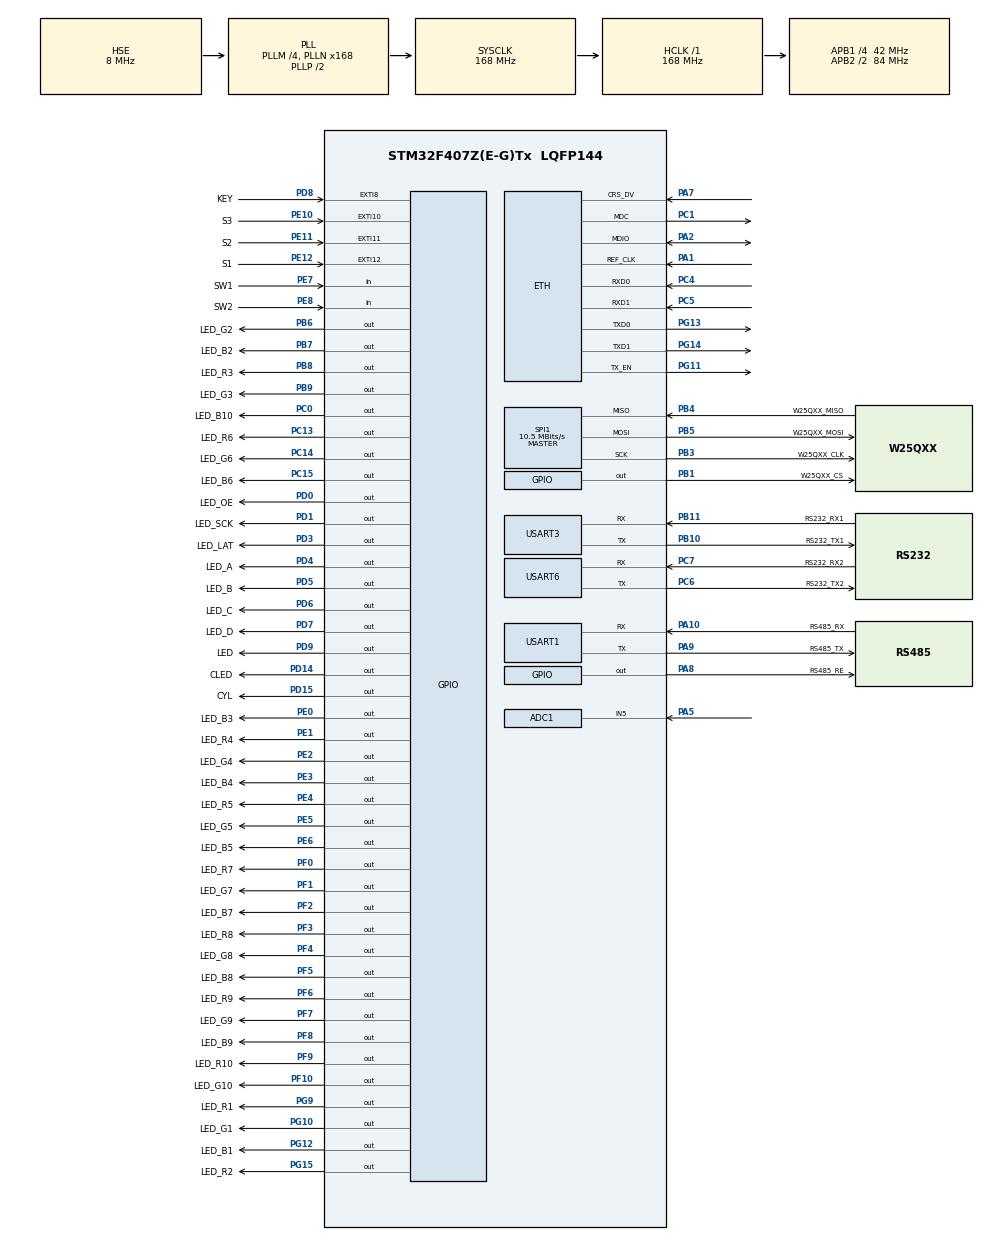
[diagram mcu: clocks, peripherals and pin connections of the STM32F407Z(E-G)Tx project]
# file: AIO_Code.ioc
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ADC1.Channel-0\#ChannelRegularConversion=ADC_CHANNEL_5
ADC1.NbrOfConversionFlag=1
ADC1.Rank-0\#ChannelRegularConversion=1
ADC1.SamplingTime-0\#ChannelRegularConversion=ADC_SAMPLETIME_3CYCLES
ADC1.master=1
Dma.Request0=USART1_RX
Dma.Request1=USART1_TX
Dma.Request2=USART3_RX
Dma.Request3=USART3_TX
Dma.Request4=USART6_RX
Dma.Request5=USART6_TX
Dma.Request6=SPI1_RX
Dma.Request7=SPI1_TX
Dma.SPI1_RX.6.Direction=DMA_PERIPH_TO_MEMORY
Dma.SPI1_RX.6.FIFOMode=DMA_FIFOMODE_DISABLE
Dma.SPI1_RX.6.Instance=DMA2_Stream0
Dma.SPI1_RX.6.MemDataAlignment=DMA_MDATAALIGN_BYTE
Dma.SPI1_RX.6.MemInc=DMA_MINC_ENABLE
Dma.SPI1_RX.6.Mode=DMA_NORMAL
Dma.SPI1_RX.6.PeriphDataAlignment=DMA_PDATAALIGN_BYTE
Dma.SPI1_RX.6.PeriphInc=DMA_PINC_DISABLE
Dma.SPI1_RX.6.Priority=DMA_PRIORITY_LOW
Dma.SPI1_TX.7.Direction=DMA_MEMORY_TO_PERIPH
Dma.SPI1_TX.7.FIFOMode=DMA_FIFOMODE_DISABLE
Dma.SPI1_TX.7.Instance=DMA2_Stream3
Dma.SPI1_TX.7.MemDataAlignment=DMA_MDATAALIGN_BYTE
Dma.SPI1_TX.7.MemInc=DMA_MINC_ENABLE
Dma.SPI1_TX.7.Mode=DMA_NORMAL
Dma.SPI1_TX.7.PeriphDataAlignment=DMA_PDATAALIGN_BYTE
Dma.SPI1_TX.7.PeriphInc=DMA_PINC_DISABLE
Dma.SPI1_TX.7.Priority=DMA_PRIORITY_LOW
Dma.USART1_RX.0.Direction=DMA_PERIPH_TO_MEMORY
Dma.USART1_RX.0.FIFOMode=DMA_FIFOMODE_DISABLE
Dma.USART1_RX.0.Instance=DMA2_Stream5
Dma.USART1_RX.0.MemDataAlignment=DMA_MDATAALIGN_BYTE
Dma.USART1_RX.0.MemInc=DMA_MINC_ENABLE
Dma.USART1_RX.0.Mode=DMA_NORMAL
Dma.USART1_RX.0.PeriphDataAlignment=DMA_PDATAALIGN_BYTE
Dma.USART1_RX.0.PeriphInc=DMA_PINC_DISABLE
Dma.USART1_RX.0.Priority=DMA_PRIORITY_LOW
Dma.USART1_TX.1.Direction=DMA_MEMORY_TO_PERIPH
Dma.USART1_TX.1.FIFOMode=DMA_FIFOMODE_DISABLE
Dma.USART1_TX.1.Instance=DMA2_Stream7
Dma.USART1_TX.1.MemDataAlignment=DMA_MDATAALIGN_BYTE
Dma.USART1_TX.1.MemInc=DMA_MINC_ENABLE
Dma.USART1_TX.1.Mode=DMA_NORMAL
Dma.USART1_TX.1.PeriphDataAlignment=DMA_PDATAALIGN_BYTE
Dma.USART1_TX.1.PeriphInc=DMA_PINC_DISABLE
Dma.USART1_TX.1.Priority=DMA_PRIORITY_LOW
Dma.USART3_RX.2.Direction=DMA_PERIPH_TO_MEMORY
Dma.USART3_RX.2.FIFOMode=DMA_FIFOMODE_DISABLE
Dma.USART3_RX.2.Instance=DMA1_Stream1
Dma.USART3_RX.2.MemDataAlignment=DMA_MDATAALIGN_BYTE
Dma.USART3_RX.2.MemInc=DMA_MINC_ENABLE
Dma.USART3_RX.2.Mode=DMA_NORMAL
Dma.USART3_RX.2.PeriphDataAlignment=DMA_PDATAALIGN_BYTE
Dma.USART3_RX.2.PeriphInc=DMA_PINC_DISABLE
Dma.USART3_RX.2.Priority=DMA_PRIORITY_LOW
Dma.USART3_TX.3.Direction=DMA_MEMORY_TO_PERIPH
Dma.USART3_TX.3.FIFOMode=DMA_FIFOMODE_DISABLE
Dma.USART3_TX.3.Instance=DMA1_Stream3
Dma.USART3_TX.3.MemDataAlignment=DMA_MDATAALIGN_BYTE
Dma.USART3_TX.3.MemInc=DMA_MINC_ENABLE
Dma.USART3_TX.3.Mode=DMA_NORMAL
Dma.USART3_TX.3.PeriphDataAlignment=DMA_PDATAALIGN_BYTE
Dma.USART3_TX.3.PeriphInc=DMA_PINC_DISABLE
Dma.USART3_TX.3.Priority=DMA_PRIORITY_LOW
Dma.USART6_RX.4.Direction=DMA_PERIPH_TO_MEMORY
Dma.USART6_RX.4.FIFOMode=DMA_FIFOMODE_DISABLE
Dma.USART6_RX.4.Instance=DMA2_Stream1
Dma.USART6_RX.4.MemDataAlignment=DMA_MDATAALIGN_BYTE
Dma.USART6_RX.4.MemInc=DMA_MINC_ENABLE
Dma.USART6_RX.4.Mode=DMA_NORMAL
Dma.USART6_RX.4.PeriphDataAlignment=DMA_PDATAALIGN_BYTE
Dma.USART6_RX.4.PeriphInc=DMA_PINC_DISABLE
Dma.USART6_RX.4.Priority=DMA_PRIORITY_LOW
Dma.USART6_TX.5.Direction=DMA_MEMORY_TO_PERIPH
Dma.USART6_TX.5.FIFOMode=DMA_FIFOMODE_DISABLE
Dma.USART6_TX.5.Instance=DMA2_Stream6
Dma.USART6_TX.5.MemDataAlignment=DMA_MDATAALIGN_BYTE
Dma.USART6_TX.5.MemInc=DMA_MINC_ENABLE
Dma.USART6_TX.5.Mode=DMA_NORMAL
Dma.USART6_TX.5.PeriphDataAlignment=DMA_PDATAALIGN_BYTE
Dma.USART6_TX.5.PeriphInc=DMA_PINC_DISABLE
Dma.USART6_TX.5.Priority=DMA_PRIORITY_LOW
ETH.MediaInterface=HAL_ETH_RMII_MODE
FREERTOS.Tasks01=defaultTask,24,256,StartDefaultTask,Default,NULL,Dynamic,NULL,NULL
FREERTOS.configTOTAL_HEAP_SIZE=32768
IWDG.Prescaler=IWDG_PRESCALER_64
IWDG.Reload=2499
LWIP.BSP.number=1
LWIP.GATEWAY_ADDRESS=192.168.001.001
LWIP.IP_ADDRESS=192.168.001.100
LWIP.LWIP_DHCP=0
LWIP.LWIP_STATS=0
LWIP.MEMP_NUM_TCP_PCB=8
LWIP.MEMP_NUM_UDP_PCB=10
LWIP.MEM_SIZE=20*1024
LWIP.NETMASK_ADDRESS=255.255.255.000
LWIP.Version=v2.1.2_Cube
LWIP0.BSP.STBoard=false
LWIP0.BSP.api=BSP_COMPONENT_DRIVER
LWIP0.BSP.component=DP83848
LWIP0.BSP.instance=DP83848
LWIP0.BSP.name=Driver_PHY
LWIP0.BSP.semaphore=S_DP83848
LWIP0.BSP.solution=DP83848
Mcu.Family=STM32F4
Mcu.Name=STM32F407Z(E-G)Tx
Mcu.Package=LQFP144
NVIC.DMA1_Stream1_IRQn=true\:8\:0\:true\:false\:true\:true\:false\:true\:true
NVIC.DMA1_Stream3_IRQn=true\:8\:0\:true\:false\:true\:true\:false\:true\:true
NVIC.DMA2_Stream0_IRQn=true\:5\:0\:false\:false\:true\:true\:false\:true\:true
NVIC.DMA2_Stream1_IRQn=true\:8\:0\:true\:false\:true\:true\:false\:true\:true
NVIC.DMA2_Stream3_IRQn=true\:5\:0\:false\:false\:true\:true\:false\:true\:true
NVIC.DMA2_Stream5_IRQn=true\:8\:0\:true\:false\:true\:true\:false\:true\:true
NVIC.DMA2_Stream6_IRQn=true\:8\:0\:true\:false\:true\:true\:false\:true\:true
NVIC.DMA2_Stream7_IRQn=true\:8\:0\:true\:false\:true\:true\:false\:true\:true
NVIC.ETH_IRQn=true\:5\:0\:false\:false\:true\:true\:false\:true\:true
NVIC.EXTI15_10_IRQn=true\:15\:0\:true\:false\:true\:false\:true\:true\:true
NVIC.EXTI9_5_IRQn=true\:15\:0\:true\:false\:true\:false\:true\:true\:true
NVIC.PriorityGroup=NVIC_PRIORITYGROUP_4
NVIC.TIM2_IRQn=true\:8\:0\:true\:false\:true\:true\:true\:true\:true
NVIC.TIM3_IRQn=true\:7\:0\:true\:false\:true\:true\:true\:true\:true
NVIC.TIM4_IRQn=true\:6\:0\:true\:false\:true\:true\:true\:true\:true
NVIC.TIM6_DAC_IRQn=true\:15\:0\:false\:false\:true\:false\:false\:true\:true
NVIC.TimeBase=TIM6_DAC_IRQn
NVIC.TimeBaseIP=TIM6
NVIC.USART1_IRQn=true\:8\:0\:true\:false\:true\:true\:false\:true\:true
NVIC.USART3_IRQn=true\:8\:0\:true\:false\:true\:true\:false\:true\:true
NVIC.USART6_IRQn=true\:8\:0\:true\:false\:true\:true\:false\:true\:true
PA1.Mode=RMII
PA1.Signal=ETH_REF_CLK
PA10.GPIO_Label=RS485_RX
PA10.Mode=Asynchronous
PA10.Signal=USART1_RX
PA13.Mode=Serial_Wire
PA13.Signal=SYS_JTMS-SWDIO
PA14.Mode=Serial_Wire
PA14.Signal=SYS_JTCK-SWCLK
PA2.Mode=RMII
PA2.Signal=ETH_MDIO
PA5.Signal=ADCx_IN5
PA7.Mode=RMII
PA7.Signal=ETH_CRS_DV
PA8.GPIO_Label=RS485_RE
PA8.Signal=GPIO_Output
PA9.GPIO_Label=RS485_TX
PA9.Mode=Asynchronous
PA9.Signal=USART1_TX
PB1.GPIO_Label=W25QXX_CS
PB1.Signal=GPIO_Output
PB10.GPIO_Label=RS232_TX1
PB10.Mode=Asynchronous
PB10.Signal=USART3_TX
PB11.GPIO_Label=RS232_RX1
PB11.Mode=Asynchronous
PB11.Signal=USART3_RX
PB3.GPIO_Label=W25QXX_CLK
PB3.Mode=Full_Duplex_Master
PB3.Signal=SPI1_SCK
PB4.GPIO_Label=W25QXX_MISO
PB4.Mode=Full_Duplex_Master
PB4.Signal=SPI1_MISO
PB5.GPIO_Label=W25QXX_MOSI
PB5.Mode=Full_Duplex_Master
PB5.Signal=SPI1_MOSI
PB6.GPIO_Label=LED_G2
PB6.Signal=GPIO_Output
PB7.GPIO_Label=LED_B2
PB7.Signal=GPIO_Output
PB8.GPIO_Label=LED_R3
PB8.Signal=GPIO_Output
PB9.GPIO_Label=LED_G3
PB9.Signal=GPIO_Output
PC0.GPIO_Label=LED_B10
PC0.Signal=GPIO_Output
PC1.Mode=RMII
PC1.Signal=ETH_MDC
PC13-ANTI_TAMP.GPIO_Label=LED_R6
PC13-ANTI_TAMP.Signal=GPIO_Output
PC14-OSC32_IN.GPIO_Label=LED_G6
PC14-OSC32_IN.Signal=GPIO_Output
PC15-OSC32_OUT.GPIO_Label=LED_B6
PC15-OSC32_OUT.Signal=GPIO_Output
PC4.Mode=RMII
PC4.Signal=ETH_RXD0
PC5.Mode=RMII
PC5.Signal=ETH_RXD1
PC6.GPIO_Label=RS232_TX2
PC6.Mode=Asynchronous
PC6.Signal=USART6_TX
PC7.GPIO_Label=RS232_RX2
PC7.Mode=Asynchronous
PC7.Signal=USART6_RX
PD0.GPIO_Label=LED_OE
PD0.Signal=GPIO_Output
PD1.GPIO_Label=LED_SCK
PD1.Signal=GPIO_Output
PD14.GPIO_Label=CLED
PD14.Signal=GPIO_Output
PD15.GPIO_Label=CYL
PD15.Signal=GPIO_Output
PD3.GPIO_Label=LED_LAT
PD3.Signal=GPIO_Output
PD4.GPIO_Label=LED_A
PD4.Signal=GPIO_Output
PD5.GPIO_Label=LED_B
PD5.Signal=GPIO_Output
PD6.GPIO_Label=LED_C
PD6.Signal=GPIO_Output
PD7.GPIO_Label=LED_D
PD7.Signal=GPIO_Output
PD8.GPIO_Label=KEY
PD8.GPIO_ModeDefaultEXTI=GPIO_MODE_IT_FALLING
PD8.GPIO_PuPd=GPIO_PULLUP
PD8.Signal=GPXTI8
PD9.GPIO_Label=LED
PD9.Signal=GPIO_Output
PE0.GPIO_Label=LED_B3
PE0.Signal=GPIO_Output
PE1.GPIO_Label=LED_R4
PE1.Signal=GPIO_Output
PE10.GPIO_Label=S3
PE10.GPIO_ModeDefaultEXTI=GPIO_MODE_IT_FALLING
PE10.GPIO_PuPd=GPIO_PULLUP
PE10.Signal=GPXTI10
PE11.GPIO_Label=S2
PE11.GPIO_ModeDefaultEXTI=GPIO_MODE_IT_FALLING
PE11.GPIO_PuPd=GPIO_PULLUP
PE11.Signal=GPXTI11
PE12.GPIO_Label=S1
PE12.GPIO_ModeDefaultEXTI=GPIO_MODE_IT_FALLING
PE12.GPIO_PuPd=GPIO_PULLUP
PE12.Signal=GPXTI12
PE2.GPIO_Label=LED_G4
PE2.Signal=GPIO_Output
PE3.GPIO_Label=LED_B4
PE3.Signal=GPIO_Output
PE4.GPIO_Label=LED_R5
PE4.Signal=GPIO_Output
PE5.GPIO_Label=LED_G5
PE5.Signal=GPIO_Output
PE6.GPIO_Label=LED_B5
PE6.Signal=GPIO_Output
PE7.GPIO_Label=SW1
PE7.GPIO_PuPd=GPIO_PULLUP
PE7.Signal=GPIO_Input
PE8.GPIO_Label=SW2
PE8.GPIO_PuPd=GPIO_PULLUP
PE8.Signal=GPIO_Input
PF0.GPIO_Label=LED_R7
PF0.Signal=GPIO_Output
PF1.GPIO_Label=LED_G7
PF1.Signal=GPIO_Output
PF10.GPIO_Label=LED_G10
PF10.Signal=GPIO_Output
PF2.GPIO_Label=LED_B7
PF2.Signal=GPIO_Output
PF3.GPIO_Label=LED_R8
PF3.Signal=GPIO_Output
PF4.GPIO_Label=LED_G8
PF4.Signal=GPIO_Output
PF5.GPIO_Label=LED_B8
PF5.Signal=GPIO_Output
PF6.GPIO_Label=LED_R9
PF6.Signal=GPIO_Output
PF7.GPIO_Label=LED_G9
PF7.Signal=GPIO_Output
PF8.GPIO_Label=LED_B9
PF8.Signal=GPIO_Output
PF9.GPIO_Label=LED_R10
PF9.Signal=GPIO_Output
PG10.GPIO_Label=LED_G1
PG10.Signal=GPIO_Output
PG11.Mode=RMII
PG11.Signal=ETH_TX_EN
PG12.GPIO_Label=LED_B1
PG12.Signal=GPIO_Output
PG13.Mode=RMII
PG13.Signal=ETH_TXD0
PG14.Mode=RMII
PG14.Signal=ETH_TXD1
PG15.GPIO_Label=LED_R2
PG15.Signal=GPIO_Output
PG9.GPIO_Label=LED_R1
PG9.Signal=GPIO_Output
PH0-OSC_IN.Mode=HSE-External-Oscillator
PH0-OSC_IN.Signal=RCC_OSC_IN
PH1-OSC_OUT.Mode=HSE-External-Oscillator
PH1-OSC_OUT.Signal=RCC_OSC_OUT
ProjectManager.HeapSize=0x200
ProjectManager.StackSize=0x400
ProjectManager.TargetToolchain=Makefile
RCC.48MHZClocksFreq_Value=84000000
RCC.AHBFreq_Value=168000000
RCC.APB1CLKDivider=RCC_HCLK_DIV4
RCC.APB1Freq_Value=42000000
RCC.APB1TimFreq_Value=84000000
RCC.APB2CLKDivider=RCC_HCLK_DIV2
RCC.APB2Freq_Value=84000000
RCC.APB2TimFreq_Value=168000000
RCC.CortexFreq_Value=168000000
RCC.HCLKFreq_Value=168000000
RCC.HSE_VALUE=8000000
RCC.HSI_VALUE=16000000
RCC.LSE_VALUE=32768
RCC.PLLM=4
RCC.PLLN=168
RCC.PLLSourceVirtual=RCC_PLLSOURCE_HSE
RCC.SYSCLKFreq_VALUE=168000000
RCC.SYSCLKSource=RCC_SYSCLKSOURCE_PLLCLK
RCC.VCOOutputFreq_Value=336000000
SH.ADCx_IN5.0=ADC1_IN5,IN5
SPI1.BaudRatePrescaler=SPI_BAUDRATEPRESCALER_8
SPI1.CalculateBaudRate=10.5 MBits/s
SPI1.Direction=SPI_DIRECTION_2LINES
SPI1.Mode=SPI_MODE_MASTER
SPI1.VirtualType=VM_MASTER
TIM2.Period=20000
TIM2.Prescaler=84
TIM3.Period=1700
TIM3.Prescaler=83
TIM4.Period=20
TIM4.Prescaler=84
USART1.VirtualMode=VM_ASYNC
USART3.VirtualMode=VM_ASYNC
USART6.VirtualMode=VM_ASYNC
VP_CRC_VS_CRC.Mode=CRC_Activate
VP_FREERTOS_VS_CMSIS_V2.Mode=CMSIS_V2
VP_IWDG_VS_IWDG.Mode=IWDG_Activate
VP_LWIP_VS_Enabled.Mode=Enabled
VP_RTC_VS_RTC_Activate.Mode=RTC_Enabled
VP_SYS_VS_tim6.Mode=TIM6
VP_TIM2_VS_ClockSourceINT.Mode=Internal
VP_TIM3_VS_ClockSourceINT.Mode=Internal
VP_TIM4_VS_ClockSourceINT.Mode=Internal
board=custom

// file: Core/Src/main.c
/* USER CODE BEGIN Header */
/**
 ******************************************************************************
 * @file           : main.c
 * @brief          : Main program body
 ******************************************************************************
 * @attention
 *
 * Copyright (c) 2025 STMicroelectronics.
 * All rights reserved.
 *
 * This software is licensed under terms that can be found in the LICENSE file
 * in the root directory of this software component.
 * If no LICENSE file comes with this software, it is provided AS-IS.
 *
 ******************************************************************************
 */
/* USER CODE END Header */
#include "main.h"
#include "adc.h"
#include "cmsis_os.h"
#include "crc.h"
#include "dma.h"
#include "gpio.h"
#include "iwdg.h"
#include "lwip.h"
#include "rtc.h"
#include "spi.h"
#include "tim.h"
#include "usart.h"

/* USER CODE BEGIN Includes */
#include "display.h"
#include "flash.h"
#include "tcp_server.h"
#include "w25qxx.h"

/* USER CODE END Includes */

/* USER CODE BEGIN PTD */
uint32_t g_ms_tick = 0;
extern u8 brightCnt;
extern u8 lightLev;
extern SPI_HandleTypeDef hspi1;
/* USER CODE END PTD */

void SystemClock_Config(void);
void MX_FREERTOS_Init(void);

int main(void)
{

    /* USER CODE BEGIN 1 */
    SCB->VTOR = FLASH_BASE | 0x40000;
    __enable_irq();
    /* USER CODE END 1 */

    /* MCU Configuration--------------------------------------------------------*/

    /* Reset of all peripherals, Initializes the Flash interface and the Systick. */
    HAL_Init();

    /* Configure the system clock */
    SystemClock_Config();

    /* Initialize all configured peripherals */
    MX_GPIO_Init();
    MX_DMA_Init();
    MX_IWDG_Init();
    MX_TIM2_Init();
    MX_TIM3_Init();
    MX_TIM4_Init();
    MX_USART1_UART_Init();
    MX_USART3_UART_Init();
    MX_USART6_UART_Init();
    MX_ADC1_Init();
    MX_SPI1_Init();
    MX_CRC_Init();
    MX_RTC_Init();
    /* USER CODE BEGIN 2 */
    W25Q256_Init(&hspi1);
    HAL_TIM_Base_Start_IT(&htim2);
    PowerOnIpSet();
    PowerOnFuncSet();
    /* USER CODE END 2 */

    /* Init scheduler */
    osKernelInitialize(); /* Call init function for freertos objects (in cmsis_os2.c) */
    MX_FREERTOS_Init();

    /* Start scheduler */
    osKernelStart();

    /* We should never get here as control is now taken by the scheduler */

    /* Infinite loop */
    while (1)
    {

    }
}

void SystemClock_Config(void)
{
    RCC_OscInitTypeDef RCC_OscInitStruct = {0};
    RCC_ClkInitTypeDef RCC_ClkInitStruct = {0};

    /** Configure the main internal regulator output voltage
     */
    __HAL_RCC_PWR_CLK_ENABLE();
    __HAL_PWR_VOLTAGESCALING_CONFIG(PWR_REGULATOR_VOLTAGE_SCALE1);

    /** Initializes the RCC Oscillators according to the specified parameters
     * in the RCC_OscInitTypeDef structure.
     */
    RCC_OscInitStruct.OscillatorType = RCC_OSCILLATORTYPE_LSI | RCC_OSCILLATORTYPE_HSE;
    RCC_OscInitStruct.HSEState = RCC_HSE_ON;
    RCC_OscInitStruct.LSIState = RCC_LSI_ON;
    RCC_OscInitStruct.PLL.PLLState = RCC_PLL_ON;
    RCC_OscInitStruct.PLL.PLLSource = RCC_PLLSOURCE_HSE;
    RCC_OscInitStruct.PLL.PLLM = 4;
    RCC_OscInitStruct.PLL.PLLN = 168;
    RCC_OscInitStruct.PLL.PLLP = RCC_PLLP_DIV2;
    RCC_OscInitStruct.PLL.PLLQ = 4;
    if (HAL_RCC_OscConfig(&RCC_OscInitStruct) != HAL_OK)
    {
        Error_Handler();
    }

    /** Initializes the CPU, AHB and APB buses clocks
     */
    RCC_ClkInitStruct.ClockType = RCC_CLOCKTYPE_HCLK | RCC_CLOCKTYPE_SYSCLK | RCC_CLOCKTYPE_PCLK1 | RCC_CLOCKTYPE_PCLK2;
    RCC_ClkInitStruct.SYSCLKSource = RCC_SYSCLKSOURCE_PLLCLK;
    RCC_ClkInitStruct.AHBCLKDivider = RCC_SYSCLK_DIV1;
    RCC_ClkInitStruct.APB1CLKDivider = RCC_HCLK_DIV4;
    RCC_ClkInitStruct.APB2CLKDivider = RCC_HCLK_DIV2;

    if (HAL_RCC_ClockConfig(&RCC_ClkInitStruct, FLASH_LATENCY_5) != HAL_OK)
    {
        Error_Handler();
    }
}

void HAL_TIM_PeriodElapsedCallback(TIM_HandleTypeDef *htim)
{
    /* USER CODE BEGIN Callback 0 */
    if (htim == &htim3)
    {
        send_hub75_buff();
    }
    if (htim->Instance == TIM4)
    {
        pwm_light_handle();
    }
    /* USER CODE END Callback 0 */
    if (htim->Instance == TIM6)
    {
        HAL_IncTick();
    }
    /* USER CODE BEGIN Callback 1 */
    if (htim == &htim2)
    {
        HAL_IWDG_Refresh(&hiwdg);
    }

    /* USER CODE END Callback 1 */
}

void Error_Handler(void)
{
    __disable_irq();
    while (1)
    {
    }
}

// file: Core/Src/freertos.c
/* USER CODE BEGIN Header */
/**
 ******************************************************************************
 * File Name          : freertos.c
 * Description        : Code for freertos applications
 ******************************************************************************
 * @attention
 *
 * Copyright (c) 2025 STMicroelectronics.
 * All rights reserved.
 *
 * This software is licensed under terms that can be found in the LICENSE file
 * in the root directory of this software component.
 * If no LICENSE file comes with this software, it is provided AS-IS.
 *
 ******************************************************************************
 */
/* USER CODE END Header */

#include "FreeRTOS.h"
#include "cmsis_os.h"
#include "main.h"
#include "task.h"

/* USER CODE BEGIN Includes */
#include "IOCtrl.h"
#include "RS232.h"
#include "RS485.h"
#include "crc.h"
#include "display.h"
#include "iwdg.h"
#include "key.h"
#include "lwip/netif.h"
#include "render.h"
#include "rtc.h"
#include "stm32f4xx_hal.h"
#include "string.h"
#include "tcp_server.h"
#include "udp_app.h"

/* USER CODE END Includes */

/* USER CODE BEGIN PTD */
extern TIM_HandleTypeDef htim3;
extern TIM_HandleTypeDef htim4;
/* USER CODE END PTD */

/* Definitions for defaultTask */
osThreadId_t defaultTaskHandle;
const osThreadAttr_t defaultTask_attributes = {
    .name = "defaultTask",
    .stack_size = 256 * 4,
    .priority = (osPriority_t)osPriorityNormal,
};

/* USER CODE BEGIN FunctionPrototypes */
osThreadId_t ledTaskHandle;
const osThreadAttr_t ledTask_attributes = {
    .name = "ledTask",
    .stack_size = 256,
    .priority = (osPriority_t)osPriorityRealtime1,
};
extern void Led_Task(void *argument);

osThreadId_t IOCtrlTaskHandle;
const osThreadAttr_t IOCtrlTask_attributes = {
    .name = "IOCtrlTask",
    .stack_size = 128 * 4,
    .priority = (osPriority_t)osPriorityLow2,
};

osThreadId_t TestKeyTaskHandle;
const osThreadAttr_t TestKeyTask_attributes = {
    .name = "TestKeyTask",
    .stack_size = 128 * 4,
    .priority = (osPriority_t)osPriorityLow2,
};

osThreadId_t Display_TaskHandle;
const osThreadAttr_t Display_Task_attributes = {
    .name = "Display_Task",
    .stack_size = 512 * 4,
    .priority = (osPriority_t)osPriorityLow3,
};
extern void Display_Task(void *argument);

osThreadId_t MotorCtrl_TaskHandle;
const osThreadAttr_t MotorCtrl_Task_attributes = {
    .name = "MotorCtrl_Task",
    .stack_size = 256 * 4,
    .priority = (osPriority_t)osPriorityRealtime1,
};
extern void MotorCtrl_Task(void *argument);

osThreadId_t MotorData_TaskHandle;
const osThreadAttr_t MotorData_Task_attributes = {
    .name = "MotorData_Task",
    .stack_size = 256 * 4,
    .priority = (osPriority_t)osPriorityRealtime2,
};
extern void MotorData_Task(void *argument);

osThreadId_t TCP_TaskHandle;
const osThreadAttr_t TCP_Task_attributes = {
    .name = "TCP_Task",
    .stack_size = 512 * 4,
    .priority = (osPriority_t)osPriorityRealtime4,
};
extern void TCP_Manager_Task(void *argument);

osThreadId_t Udp_TaskHandle;
const osThreadAttr_t Udp_Task_attributes = {
    .name = "Udp_Task",
    .stack_size = 256 * 4,
    .priority = (osPriority_t)osPriorityRealtime4,
};
extern void UDP_Manager_Task(void *argument);

osThreadId_t TcpParse_TaskHandle;
const osThreadAttr_t TcpParse_Task_attributes = {
    .name = "TcpParse_Task",
    .stack_size = 512 * 4,
    .priority = (osPriority_t)osPriorityRealtime5,
};
extern void TcpParse_Task(void *argument);

osThreadId_t Iap_TaskHandle;
const osThreadAttr_t IapTask_attributes = {
    .name = "iap_handle_task",
    .stack_size = 512 * 4,
    .priority = (osPriority_t)osPriorityRealtime5,
};
extern void Iap_Task(void *argument);

osThreadId_t RS485_TaskHandle;
const osThreadAttr_t RS485_Task_attributes = {
    .name = "RS485_Task",
    .stack_size = 512 * 4,
    .priority = (osPriority_t)osPriorityRealtime5,
};
extern void RS485_Task(void *argument);

osThreadId_t RS232_TaskHandle;
const osThreadAttr_t RS232_Task_attributes = {
    .name = "RS232_Task",
    .stack_size = 512 * 4,
    .priority = (osPriority_t)osPriorityRealtime5,
};
extern void RS232_Task(void *argument);
/* USER CODE END FunctionPrototypes */

void StartDefaultTask(void *argument);

extern void MX_LWIP_Init(void);
void MX_FREERTOS_Init(void); /* (MISRA C 2004 rule 8.1) */

void MX_FREERTOS_Init(void)
{

    /* Create the thread(s) */
    /* creation of defaultTask */
    defaultTaskHandle = osThreadNew(StartDefaultTask, NULL, &defaultTask_attributes);

    /* USER CODE BEGIN RTOS_THREADS */
    /* add threads, ... */
    ledTaskHandle = osThreadNew(Led_Task, NULL, &ledTask_attributes);
    configASSERT(ledTaskHandle != NULL);
    IOCtrlTaskHandle = osThreadNew(BSP_S123_Task, NULL, &IOCtrlTask_attributes);
    configASSERT(IOCtrlTaskHandle != NULL);
    TestKeyTaskHandle = osThreadNew(TestKey_Task, NULL, &TestKeyTask_attributes);
    configASSERT(TestKeyTaskHandle != NULL);
    Display_TaskHandle = osThreadNew(Display_Task, NULL, &Display_Task_attributes);
    configASSERT(Display_TaskHandle != NULL);
    MotorCtrl_TaskHandle = osThreadNew(MotorCtrl_Task, NULL, &MotorCtrl_Task_attributes);
    configASSERT(MotorCtrl_TaskHandle != NULL);
    MotorData_TaskHandle = osThreadNew(MotorData_Task, NULL, &MotorData_Task_attributes);
    configASSERT(MotorData_TaskHandle != NULL);
    RS485_Init();
    RS485_TaskHandle = osThreadNew(RS485_Task, NULL, &RS485_Task_attributes);
    configASSERT(RS485_TaskHandle != NULL);
    RS232_Init();
    RS232_TaskHandle = osThreadNew(RS232_Task, NULL, &RS232_Task_attributes);
    configASSERT(RS232_TaskHandle != NULL);
    /* USER CODE END RTOS_THREADS */

}

void StartDefaultTask(void *argument)
{
    /* init code for LWIP */
    MX_LWIP_Init();
    /* USER CODE BEGIN StartDefaultTask */
    TCP_Server_Init();
    TCP_TaskHandle = osThreadNew(TCP_Manager_Task, NULL, &TCP_Task_attributes);
    configASSERT(TCP_TaskHandle != NULL);
    UDP_Init();
    Udp_TaskHandle = osThreadNew(UDP_Manager_Task, NULL, &Udp_Task_attributes);
    configASSERT(Udp_TaskHandle != NULL);
    TcpParse_TaskHandle = osThreadNew(TcpParse_Task, NULL, &TcpParse_Task_attributes);
    configASSERT(TcpParse_TaskHandle != NULL);
    Iap_TaskHandle = osThreadNew(Iap_Task, NULL, &IapTask_attributes);
    configASSERT(Iap_TaskHandle != NULL);
    /* Infinite loop */
    for (;;)
    {
        osDelay(1);
    }
    /* USER CODE END StartDefaultTask */
}

/* USER CODE BEGIN Application */
void Led_Task(void *argument)
{

    uint32_t run_time = 0;

    for (;;)
    {
        if (run_time >= 60)
            HAL_RTCEx_BKUPWrite(&hrtc, RTC_BKP_DR1, 0);
        else
            run_time++;

        HAL_GPIO_TogglePin(GPIOD, GPIO_PIN_9);

        osDelay(500);
    }
}

void vApplicationStackOverflowHook(TaskHandle_t xTask, char *pcTaskName)
{
    while (1)
        ;
}
/* USER CODE END Application */
